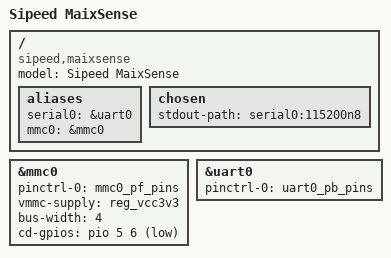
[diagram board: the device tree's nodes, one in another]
// SPDX-License-Identifier: (GPL-2.0+ OR MIT)
// Copyright (c) 2021 Sipeed

/dts-v1/;

#include "sun50i-r329-maix-iia.dtsi"

/ {
	model = "Sipeed MaixSense";
	compatible = "sipeed,maixsense", "sipeed,maix-iia",
		     "allwinner,sun50i-r329";

	aliases {
		serial0 = &uart0;
		mmc0 = &mmc0;
	};

	chosen {
		stdout-path = "serial0:115200n8";
	};
};

&mmc0 {
	pinctrl-names = "default";
	pinctrl-0 = <&mmc0_pf_pins>;

	vmmc-supply = <&reg_vcc3v3>;
	bus-width = <4>;
	cd-gpios = <&pio 5 6 GPIO_ACTIVE_LOW>; /* PF6 */
	status = "okay";
};

&uart0 {
	pinctrl-names = "default";
	pinctrl-0 = <&uart0_pb_pins>;
	status = "okay";
};
